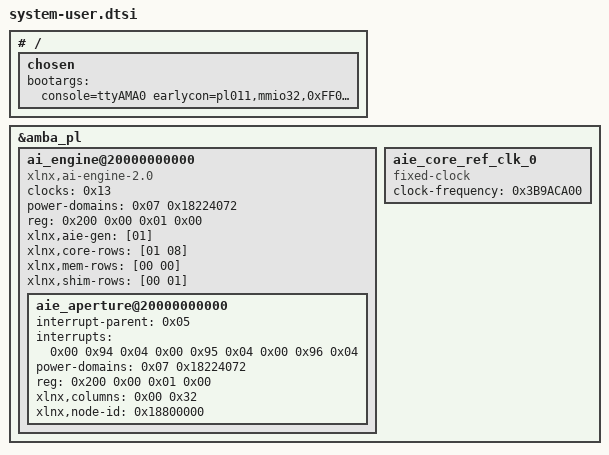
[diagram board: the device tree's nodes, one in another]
#/*
#Copyright (C) 2023, Advanced Micro Devices, Inc. All rights reserved.
#SPDX-License-Identifier: X11
#*/

/ {
chosen {
   bootargs = "console=ttyAMA0 earlycon=pl011,mmio32,0xFF000000,115200n8 clk_ignore_unused root=/dev/mmcblk0p2 rw rootwait cma=512M";
      };
   };

&amba_pl {
	ai_engine@20000000000 {
		#address-cells = <0x02>;
		#size-cells = <0x02>;
		clock-names = "aclk0";
		clocks = <0x13>;
		compatible = "xlnx,ai-engine-2.0\0xlnx,ai-engine-v2.0";
		power-domains = <0x07 0x18224072>;
		ranges;
		reg = <0x200 0x00 0x01 0x00>;
		xlnx,aie-gen = [01];
		xlnx,core-rows = [01 08];
		xlnx,mem-rows = [00 00];
		xlnx,shim-rows = [00 01];

		aie_aperture@20000000000 {
			#address-cells = <0x02>;
			#size-cells = <0x02>;
			interrupt-names = "interrupt1\0interrupt2\0interrupt3";
			interrupt-parent = <0x05>;
			interrupts = <0x00 0x94 0x04 0x00 0x95 0x04 0x00 0x96 0x04>;
			power-domains = <0x07 0x18224072>;
			reg = <0x200 0x00 0x01 0x00>;
			xlnx,columns = <0x00 0x32>;
			xlnx,node-id = <0x18800000>;
		};
	};
	aie_core_ref_clk_0 {
		#clock-cells = <0x00>;
		clock-frequency = <0x3B9ACA00>;
		compatible = "fixed-clock";
		phandle = <0x13>;
	};
	
};
